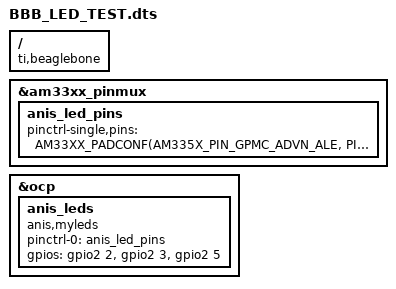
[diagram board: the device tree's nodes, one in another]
/dts-v1/;
/plugin/;

#include "dt-bindings/gpio/gpio.h"
#include "dt-bindings/pinctrl/am33xx.h"

/ {
    compatible = "ti,beaglebone", "ti,beaglebone-black";

    fragment@0 {
        target = <&am33xx_pinmux>;
        __overlay__ {
            anis_led_pins {
                pinctrl-single,pins = <
					AM33XX_PADCONF(AM335X_PIN_GPMC_ADVN_ALE, PIN_OUTPUT, MUX_MODE7)
					AM33XX_PADCONF(AM335X_PIN_GPMC_OEN_REN,  PIN_OUTPUT, MUX_MODE7)
					AM33XX_PADCONF(AM335X_PIN_GPMC_WEN, 	 PIN_OUTPUT, MUX_MODE7)
                >;
            };
        };
    };

    fragment@1 {
        target = <&ocp>;
        __overlay__ {
            anis_leds {
                compatible = "anis,myleds";
                pinctrl-names = "default";
                pinctrl-0 = <&anis_led_pins>;

                gpios = <&gpio2 2 GPIO_ACTIVE_HIGH>,
                        <&gpio2 3 GPIO_ACTIVE_HIGH>,
                        <&gpio2 5 GPIO_ACTIVE_HIGH>;
            };
        };
    };
};
